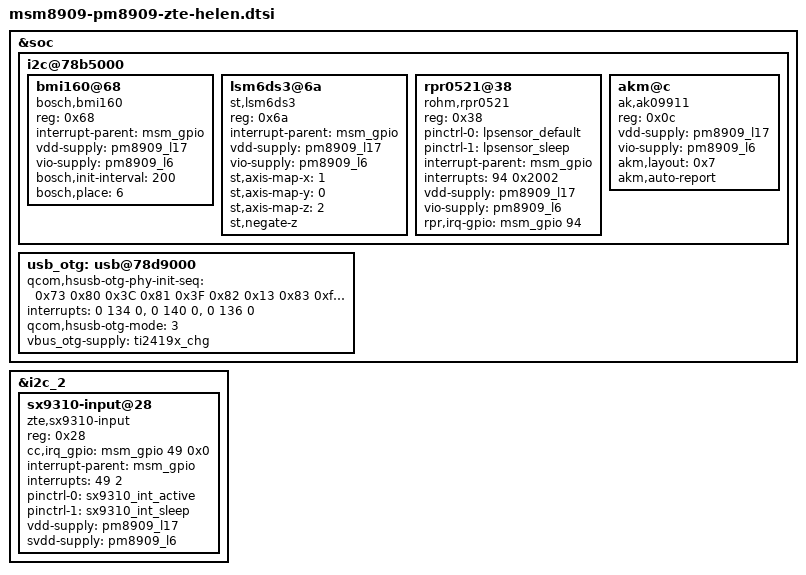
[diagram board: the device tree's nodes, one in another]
/*
 * Copyright (c) 2014-2015, The Linux Foundation. All rights reserved.
 *
 * This program is free software; you can redistribute it and/or modify
 * it under the terms of the GNU General Public License version 2 and
 * only version 2 as published by the Free Software Foundation.
 *
 * This program is distributed in the hope that it will be useful,
 * but WITHOUT ANY WARRANTY; without even the implied warranty of
 * MERCHANTABILITY or FITNESS FOR A PARTICULAR PURPOSE.  See the
 * GNU General Public License for more details.
 */

#include "touch-key-backlight-helen.dtsi"


&soc {
	i2c@78b5000 { /* BLSP1 QUP1 */
		bmi160@68 {
			compatible = "bosch,bmi160";
			reg = <0x68>;
			interrupt-parent = <&msm_gpio>;
			vdd-supply = <&pm8909_l17>;
			vio-supply = <&pm8909_l6>;
			bosch,init-interval = <200>;
			bosch,place = <6>;
		};

		lsm6ds3@6a {
			compatible = "st,lsm6ds3";
			reg = <0x6a>;
			interrupt-parent = <&msm_gpio>;
			vdd-supply = <&pm8909_l17>;
			vio-supply = <&pm8909_l6>;
			st,axis-map-x = <1>;
			st,axis-map-y = <0>;
			st,axis-map-z = <2>;
			/* st,negate-x; */
			/* st,negate-y; */
			st,negate-z;
		};

		rpr0521@38 {
			compatible = "rohm,rpr0521";
			reg = <0x38>;
			pinctrl-names = "lpsensor_default","lpsensor_sleep";
			pinctrl-0 = <&lpsensor_default>;
			pinctrl-1 = <&lpsensor_sleep>;
			interrupt-parent = <&msm_gpio>;
			interrupts = <94 0x2002>;
			vdd-supply = <&pm8909_l17>;
			vio-supply = <&pm8909_l6>;
			rpr,irq-gpio = <&msm_gpio 94 0x2002>;
		};

		akm@c {
			compatible = "ak,ak09911";
			reg = <0x0c>;
			vdd-supply = <&pm8909_l17>;
			vio-supply = <&pm8909_l6>;
			akm,layout = <0x7>;
			akm,auto-report;
		};

	};
	usb_otg: usb@78d9000 {
		qcom,hsusb-otg-phy-init-seq =
			<0x73 0x80 0x3C 0x81 0x3F 0x82 0x13 0x83 0xffffffff>;
	};
};

&usb_otg {
	interrupts = <0 134 0>,<0 140 0>,<0 136 0>;
	interrupt-names = "core_irq", "async_irq", "phy_irq";

	qcom,hsusb-otg-mode = <3>;
	vbus_otg-supply = <&ti2419x_chg>;
};

&i2c_2 { /* BLSP2 QUP1 */
	sx9310-input@28 {
		compatible = "zte,sx9310-input";
		reg = <0x28>;
		cc,irq_gpio = <&msm_gpio 49 0x0>;
		interrupt-parent = <&msm_gpio>;
		interrupts = <49 2>;
		interrupt-names = "sx9310_irq";
		pinctrl-names = "sx9310_active", "sx9310_sleep";
		pinctrl-0 = <&sx9310_int_active>;
		pinctrl-1 = <&sx9310_int_sleep>;
		vdd-supply = <&pm8909_l17>;
		svdd-supply = <&pm8909_l6>;
	};
};
